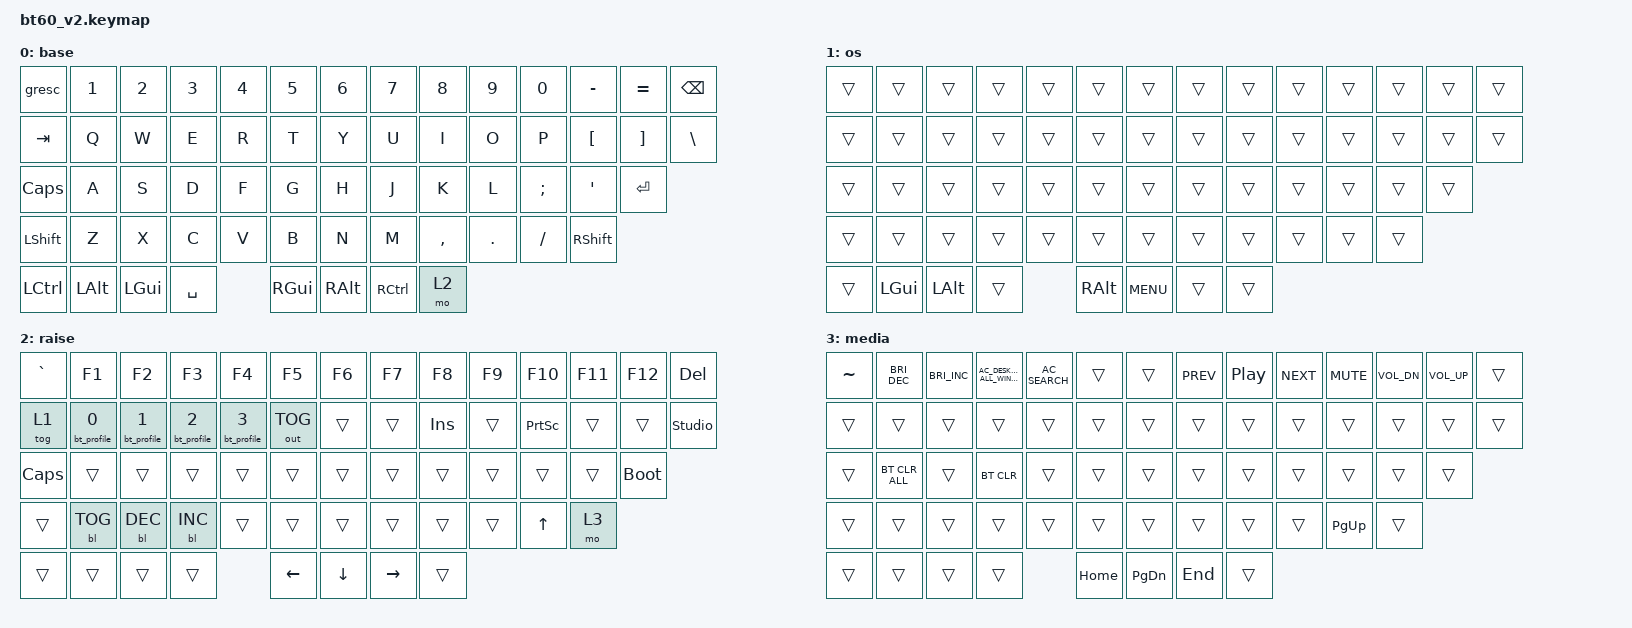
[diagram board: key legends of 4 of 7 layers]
#include <behaviors.dtsi>
#include <dt-bindings/zmk/keys.h>
#include <dt-bindings/zmk/bt.h>
#include <dt-bindings/zmk/rgb.h>
#include <dt-bindings/zmk/backlight.h>
#include <dt-bindings/zmk/outputs.h>

#define ANSI

/ {

 macros {
        bt_profile: bt_profile {
            compatible = "zmk,behavior-macro-one-param";
            #binding-cells = <1>;
            bindings = <&macro_param_1to1>, <&bt BT_DISC 0>, <&macro_wait_time 50>, <&bt BT_DISC 1>, <&macro_wait_time 50>, <&bt BT_DISC 2>, <&macro_wait_time 50>, <&bt BT_DISC 3>, <&macro_wait_time 50>, <&bt BT_SEL MACRO_PLACEHOLDER>;
        };
    };

  chosen {
    zmk,physical-layout = &layout_60_ansi;
  };

  keymap {
    compatible = "zmk,keymap";

    base {
      display-name = "base";
      bindings = <
        &gresc &kp N1 &kp N2 &kp N3 &kp N4 &kp N5 &kp N6 &kp N7 &kp N8 &kp N9 &kp N0 &kp MINUS &kp EQUAL &kp BSPC
        &kp TAB  &kp Q  &kp W  &kp E  &kp R  &kp T  &kp Y  &kp U  &kp I  &kp O  &kp P  &kp LBKT &kp RBKT &kp BSLH
        &kp CAPS &kp A  &kp S  &kp D  &kp F  &kp G  &kp H  &kp J  &kp K  &kp L  &kp SEMI &kp SQT &kp RET
        &kp LSHFT &kp Z  &kp X  &kp C  &kp V  &kp B  &kp N  &kp M  &kp COMMA &kp DOT &kp FSLH &kp RSHFT
        &kp LCTRL &kp LALT &kp LGUI &kp SPACE &kp RGUI &kp RALT &kp RCTRL &mo 2
      >;
    };

    os {
      display-name = "os";
      bindings = <
        &trans &trans &trans &trans &trans &trans &trans &trans &trans &trans &trans &trans &trans &trans
        &trans &trans &trans &trans &trans &trans &trans &trans &trans &trans &trans &trans &trans &trans
        &trans &trans &trans &trans &trans &trans &trans &trans &trans &trans &trans &trans &trans
        &trans &trans &trans &trans &trans &trans &trans &trans &trans &trans &trans &trans
        &trans &kp LGUI &kp LALT &trans &kp RALT &kp C_MENU &trans &trans
      >;
    };

    raise {
      display-name = "raise";
      bindings = <
        &kp GRAVE &kp F1 &kp F2 &kp F3 &kp F4 &kp F5 &kp F6 &kp F7 &kp F8 &kp F9 &kp F10 &kp F11 &kp F12 &kp DEL
        &tog 1 &bt_profile 0 &bt_profile 1 &bt_profile 2 &bt_profile 3 &out OUT_TOG &trans &trans &kp INS &trans &kp PSCRN &trans &trans &studio_unlock
        &kp CAPS &trans &trans &trans &trans &trans &trans &trans &trans &trans &trans &trans &bootloader
        &trans &bl BL_TOG &bl BL_DEC &bl BL_INC &trans &trans &trans &trans &trans &trans &kp UP &mo 3
        &trans &trans &trans &trans &kp LEFT &kp DOWN &kp RIGHT &trans
      >;
    };

    media {
      display-name = "media";
      bindings = <
        &kp TILDE &kp C_BRI_DEC &kp C_BRI_INC &kp C_AC_DESKTOP_SHOW_ALL_WINDOWS &kp C_AC_SEARCH &trans &trans &kp C_PREV &kp C_PLAY_PAUSE &kp C_NEXT &kp C_MUTE &kp C_VOL_DN &kp C_VOL_UP &trans
        &trans &trans &trans &trans &trans &trans &trans &trans &trans &trans &trans &trans &trans &trans
        &trans &bt BT_CLR_ALL &trans &bt BT_CLR &trans &trans &trans &trans &trans &trans &trans &trans &trans
        &trans &trans &trans &trans &trans &trans &trans &trans &trans &trans &kp PG_UP &trans
        &trans &trans &trans &trans &kp HOME &kp PG_DN &kp END &trans
      >;
    };

    layer4 {
      display-name = "layer4";
      bindings = <
        &trans &trans &trans &trans &trans &trans &trans &trans &trans &trans &trans &trans &trans &trans
        &trans &trans &trans &trans &trans &trans &trans &trans &trans &trans &trans &trans &trans
        &trans &trans &trans &trans &trans &trans &trans &trans &trans &trans &trans &trans &trans
        &trans &trans &trans &trans &trans &trans &trans &trans &trans &trans &trans &trans
        &trans &trans &trans &trans &trans &trans &trans &trans
      >;
    };

    layer5 {
      display-name = "layer5";
      bindings = <
        &trans &trans &trans &trans &trans &trans &trans &trans &trans &trans &trans &trans &trans &trans
        &trans &trans &trans &trans &trans &trans &trans &trans &trans &trans &trans &trans &trans
        &trans &trans &trans &trans &trans &trans &trans &trans &trans &trans &trans &trans &trans
        &trans &trans &trans &trans &trans &trans &trans &trans &trans &trans &trans &trans
        &trans &trans &trans &trans &trans &trans &trans &trans
      >;
    };

    layer6 {
      display-name = "layer6";
      bindings = <
        &trans &trans &trans &trans &trans &trans &trans &trans &trans &trans &trans &trans &trans &trans
        &trans &trans &trans &trans &trans &trans &trans &trans &trans &trans &trans &trans &trans
        &trans &trans &trans &trans &trans &trans &trans &trans &trans &trans &trans &trans &trans
        &trans &trans &trans &trans &trans &trans &trans &trans &trans &trans &trans &trans
        &trans &trans &trans &trans &trans &trans &trans &trans
      >;
    };
  };
};
